# R7FA6M3AH register map
Vendor: Renesas; Series: RA6; File version: 1.2
CPU: CM4 r0p1, little endian, MPU, FPU, VTOR, 4 interrupt priority bits
Registers are 32-bit, read-write, reset 0x0 unless marked. A register's access mark holds for its fields unless they carry their own. Offsets are from the block's base; [hi:lo] are bit positions; {n}, {i} and the like mark numbered series.

## ICU — Interrupt Controller
Base 0x40006000
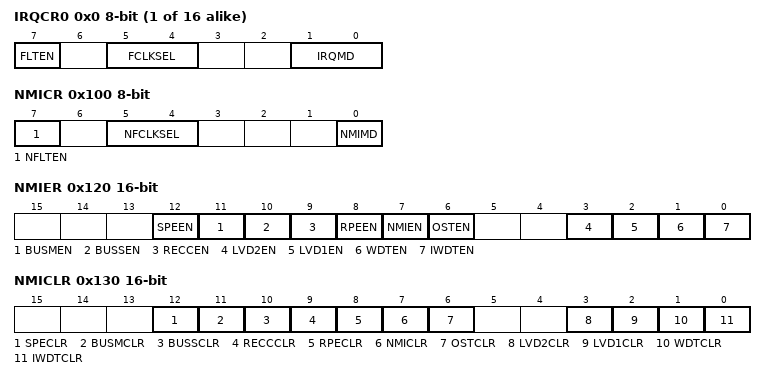
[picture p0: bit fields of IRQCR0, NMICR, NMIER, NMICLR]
{0x0+i} IRQCR{i} (i=0..15) 8-bit — IRQ Control Register {i}
  [7] FLTEN — IRQ Digital Filter Enable
  [5:4] FCLKSEL — IRQ Digital Filter Sampling Clock
  [1:0] IRQMD — IRQ Detection Sense Select
0x100 NMICR 8-bit — NMI Pin Interrupt Control Register
  [7] NFLTEN — NMI Digital Filter Enable
  [5:4] NFCLKSEL — NMI Digital Filter Sampling Clock
  [0] NMIMD — NMI Detection Set
0x120 NMIER 16-bit — Non,Maskable Interrupt Enable Register
  [12] SPEEN — MPU Stack Error Interrupt Enable
  [11] BUSMEN — MPU Bus Master Error Interrupt Enable
  [10] BUSSEN — MPU Bus Slave Error Interrupt Enable
  [9] RECCEN — RAM ECC Error Interrupt Enable
  [8] RPEEN — RAM Parity Error Interrupt Enable
  [7] NMIEN — NMI Pin Interrupt Enable
  [6] OSTEN — Oscillation Stop Detection Interrupt Enable
  [3] LVD2EN — Voltage,Monitoring 2 Interrupt Enable
  [2] LVD1EN — Voltage,Monitoring 1 Interrupt Enable
  [1] WDTEN — WDT Underflow/Refresh Error Interrupt Enable
  [0] IWDTEN — IWDT Underflow/Refresh Error Interrupt Enable
0x130 NMICLR 16-bit wo — Non,Maskable Interrupt Status Clear Register
  [12] SPECLR — SPEST Clear
  [11] BUSMCLR — BUSMST Clear
  [10] BUSSCLR — BUSSST Clear
  [9] RECCCLR — RECCST Clear
  [8] RPECLR — RPEST Clear
  [7] NMICLR — NMIST Clear
  [6] OSTCLR — OSTST Clear
  [3] LVD2CLR — LVD2ST Clear
  [2] LVD1CLR — LVD1ST Clear
  [1] WDTCLR — WDTST Clear
  [0] IWDTCLR — IWDTST Clear
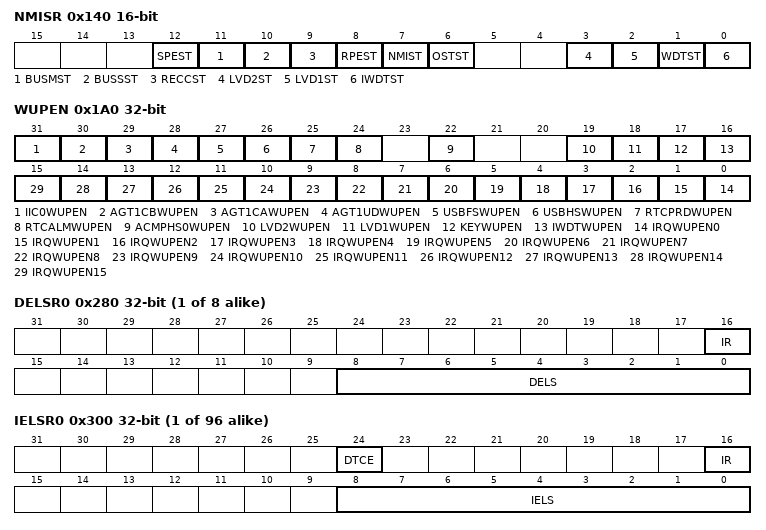
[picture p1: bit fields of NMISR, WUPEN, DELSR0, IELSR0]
0x140 NMISR 16-bit ro — Non,Maskable Interrupt Status Register
  [12] SPEST — MPU Stack Error Interrupt Status Flag
  [11] BUSMST — MPU Bus Master Error Interrupt Status Flag
  [10] BUSSST — MPU Bus Slave Error Interrupt Status Flag
  [9] RECCST — RAM ECC Error Interrupt Status Flag
  [8] RPEST — RAM Parity Error Interrupt Status Flag
  [7] NMIST — NMI Status Flag
  [6] OSTST — Oscillation Stop Detection Interrupt Status Flag
  [3] LVD2ST — Voltage,Monitoring 2 Interrupt Status Flag
  [2] LVD1ST — Voltage,Monitoring 1 Interrupt Status Flag
  [1] WDTST — WDT Underflow/Refresh Error Status Flag
  [0] IWDTST — IWDT Underflow/Refresh Error Status Flag
0x1A0 WUPEN — Wake Up interrupt enable register
  [31] IIC0WUPEN — IIC0 address match interrupt S/W standby returns enable bit
  [30] AGT1CBWUPEN — AGT1 compare match B interrupt S/W standby returns enable bit
  [29] AGT1CAWUPEN — AGT1 compare match A interrupt S/W standby returns enable bit
  [28] AGT1UDWUPEN — AGT1 underflow interrupt S/W standby returns enable bit
  [27] USBFSWUPEN — USBFS interrupt S/W standby returns enable bit
  [26] USBHSWUPEN — USBHS interrupt S/W standby returns enable bit
  [25] RTCPRDWUPEN — RCT period interrupt S/W standby returns enable bit
  [24] RTCALMWUPEN — RTC alarm interrupt S/W standby returns enable bit
  [22] ACMPHS0WUPEN — ACMPHS0 interrupt S/W standby returns enable bit
  [19] LVD2WUPEN — LVD2 interrupt S/W standby returns enable bit
  [18] LVD1WUPEN — LVD1 interrupt S/W standby returns enable bit
  [17] KEYWUPEN — Key interrupt S/W standby returns enable bit
  [16] IWDTWUPEN — IWDT interrupt S/W standby returns enable bit
  [n] IRQWUPEN{n} (n=0..15) — IRQ{n} interrupt S/W standby returns enable bit
0x200 SELSR0 16-bit — SYS Event Link Setting Register
  [8:0] SELS — SYS Event Link Select
{0x280+4i} DELSR{i} (i=0..7) — DMAC Event Link Setting Register {i}
  [16] IR — Interrupt Status Flag for DMAC
  [8:0] DELS — DMAC Event Link Select
{0x300+4i} IELSR{i} (i=0..95) — INT Event Link Setting Register {i}
  [24] DTCE — DTC Activation Enable
  [16] IR — Interrupt Status Flag
  [8:0] IELS — Event selection to NVIC

## SRAM — SRAM Control
Base 0x40002000
0x00 PARIOAD 8-bit — SRAM Parity Error Operation After Detection Register
  [0] OAD — Operation after Detection
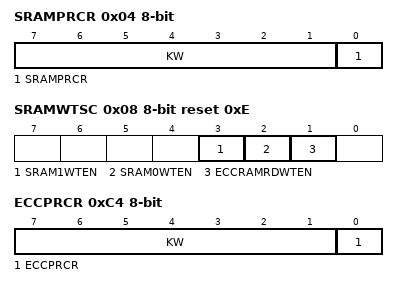
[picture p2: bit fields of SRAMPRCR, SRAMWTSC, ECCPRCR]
0x04 SRAMPRCR 8-bit — SRAM Protection Register
  [7:1] KW wo — Write Key Code
  [0] SRAMPRCR — Register Write Control
0x08 SRAMWTSC 8-bit reset 0xE — RAM Wait State Control Register
  [3] SRAM1WTEN — SRAM1 Wait Enable
  [2] SRAM0WTEN — SRAM0 Wait Enable
  [1] ECCRAMRDWTEN — ECCRAM Read wait enable
0xC0 ECCMODE 8-bit — ECCRAM Operating Mode Control Register
  [1:0] ECCMOD — ECC Operating Mode Select
0xC1 ECC2STS 8-bit — ECCRAM 2-Bit Error Status Register
  [0] ECC2ERR write-0-clears read-modifies — ECC 2-Bit Error Status
0xC2 ECC1STSEN 8-bit — ECCRAM 1-Bit Error Information Update Enable Register
  [0] E1STSEN — ECC 1-Bit Error Information Update Enable
0xC3 ECC1STS 8-bit — ECCRAM 1-Bit Error Status Register
  [0] ECC1ERR write-0-clears read-modifies — ECC 1-Bit Error Status
0xC4 ECCPRCR 8-bit — ECCRAM Protection Register
  [7:1] KW wo — Write Key Code
  [0] ECCPRCR — ECCRAMETST Register Write Control
0xD4 ECCETST 8-bit — ECC Test Control Register
  [0] TSTBYP — ECC Bypass Select
0xD8 ECCOAD 8-bit — RAM ECC Error Operation After Detection Register
  [0] OAD — Operation after Detection
